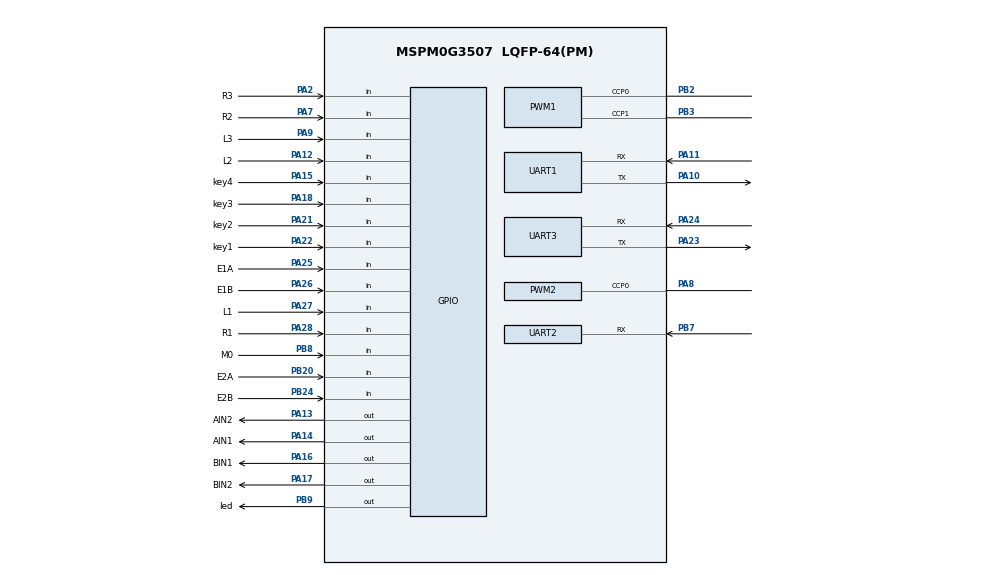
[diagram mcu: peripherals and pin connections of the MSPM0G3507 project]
/**
 * These arguments were used when this file was generated. They will be automatically applied on subsequent loads
 * via the GUI or CLI. Run CLI with '--help' for additional information on how to override these arguments.
 * @cliArgs --device "MSPM0G350X" --part "Default" --package "LQFP-64(PM)" --product "mspm0_sdk@2.05.01.00"
 * @v2CliArgs --device "MSPM0G3507" --package "LQFP-64(PM)" --product "mspm0_sdk@2.05.01.00"
 * @versions {"tool":"1.24.2+4234"}
 */

/**
 * Import the modules used in this configuration.
 */
const GPIO    = scripting.addModule("/ti/driverlib/GPIO", {}, false);
const GPIO1   = GPIO.addInstance();
const GPIO2   = GPIO.addInstance();
const GPIO3   = GPIO.addInstance();
const GPIO4   = GPIO.addInstance();
const GPIO5   = GPIO.addInstance();
const GPIO6   = GPIO.addInstance();
const GPIO7   = GPIO.addInstance();
const I2C     = scripting.addModule("/ti/driverlib/I2C", {}, false);
const I2C1    = I2C.addInstance();
const PWM     = scripting.addModule("/ti/driverlib/PWM", {}, false);
const PWM1    = PWM.addInstance();
const PWM2    = PWM.addInstance();
const SYSCTL  = scripting.addModule("/ti/driverlib/SYSCTL");
const SYSTICK = scripting.addModule("/ti/driverlib/SYSTICK");
const TIMER   = scripting.addModule("/ti/driverlib/TIMER", {}, false);
const TIMER1  = TIMER.addInstance();
const TIMER2  = TIMER.addInstance();
const UART    = scripting.addModule("/ti/driverlib/UART", {}, false);
const UART1   = UART.addInstance();
const UART2   = UART.addInstance();
const UART3   = UART.addInstance();

/**
 * Write custom configuration values to the imported modules.
 */
const divider7       = system.clockTree["PLL_PDIV"];
divider7.divideValue = 2;

const divider9       = system.clockTree["UDIV"];
divider9.divideValue = 2;

const gate7  = system.clockTree["MFCLKGATE"];
gate7.enable = true;

const multiplier2         = system.clockTree["PLL_QDIV"];
multiplier2.multiplyValue = 5;

const mux8       = system.clockTree["HSCLKMUX"];
mux8.inputSelect = "HSCLKMUX_SYSPLL2X";

GPIO1.$name                         = "KEY";
GPIO1.associatedPins.create(4);
GPIO1.associatedPins[0].direction   = "INPUT";
GPIO1.associatedPins[0].$name       = "key1";
GPIO1.associatedPins[0].pin.$assign = "PA22";
GPIO1.associatedPins[1].$name       = "key2";
GPIO1.associatedPins[1].direction   = "INPUT";
GPIO1.associatedPins[1].pin.$assign = "PA21";
GPIO1.associatedPins[2].$name       = "key3";
GPIO1.associatedPins[2].direction   = "INPUT";
GPIO1.associatedPins[2].pin.$assign = "PA18";
GPIO1.associatedPins[3].$name       = "key4";
GPIO1.associatedPins[3].direction   = "INPUT";
GPIO1.associatedPins[3].pin.$assign = "PA15";

const Board = scripting.addModule("/ti/driverlib/Board", {}, false);

GPIO2.$name                         = "LED";
GPIO2.associatedPins[0].$name       = "led";
GPIO2.associatedPins[0].pin.$assign = "PB9";

GPIO3.port                          = "PORTA";
GPIO3.$name                         = "BIN";
GPIO3.associatedPins.create(2);
GPIO3.associatedPins[0].$name       = "BIN1";
GPIO3.associatedPins[0].pin.$assign = "PA16";
GPIO3.associatedPins[1].$name       = "BIN2";
GPIO3.associatedPins[1].pin.$assign = "PA17";

GPIO4.port                          = "PORTA";
GPIO4.$name                         = "AIN";
GPIO4.associatedPins.create(2);
GPIO4.associatedPins[0].$name       = "AIN1";
GPIO4.associatedPins[0].pin.$assign = "PA14";
GPIO4.associatedPins[1].$name       = "AIN2";
GPIO4.associatedPins[1].pin.$assign = "PA13";

GPIO5.$name                               = "ENCODERA";
GPIO5.associatedPins.create(2);
GPIO5.associatedPins[0].$name             = "E1A";
GPIO5.associatedPins[0].direction         = "INPUT";
GPIO5.associatedPins[0].interruptEn       = true;
GPIO5.associatedPins[0].internalResistor  = "PULL_UP";
GPIO5.associatedPins[0].interruptPriority = "0";
GPIO5.associatedPins[0].polarity          = "RISE_FALL";
GPIO5.associatedPins[0].pin.$assign       = "PA25";
GPIO5.associatedPins[1].$name             = "E1B";
GPIO5.associatedPins[1].direction         = "INPUT";
GPIO5.associatedPins[1].interruptEn       = true;
GPIO5.associatedPins[1].internalResistor  = "PULL_UP";
GPIO5.associatedPins[1].interruptPriority = "0";
GPIO5.associatedPins[1].polarity          = "RISE_FALL";
GPIO5.associatedPins[1].pin.$assign       = "PA26";

GPIO6.$name                               = "ENCODERB";
GPIO6.associatedPins.create(2);
GPIO6.associatedPins[0].$name             = "E2A";
GPIO6.associatedPins[0].direction         = "INPUT";
GPIO6.associatedPins[0].interruptEn       = true;
GPIO6.associatedPins[0].internalResistor  = "PULL_DOWN";
GPIO6.associatedPins[0].interruptPriority = "0";
GPIO6.associatedPins[0].polarity          = "RISE_FALL";
GPIO6.associatedPins[0].pin.$assign       = "PB20";
GPIO6.associatedPins[1].$name             = "E2B";
GPIO6.associatedPins[1].direction         = "INPUT";
GPIO6.associatedPins[1].interruptEn       = true;
GPIO6.associatedPins[1].internalResistor  = "PULL_DOWN";
GPIO6.associatedPins[1].interruptPriority = "0";
GPIO6.associatedPins[1].polarity          = "RISE_FALL";
GPIO6.associatedPins[1].pin.$assign       = "PB24";

GPIO7.$name                              = "HX_X17";
GPIO7.associatedPins.create(7);
GPIO7.associatedPins[0].$name            = "L3";
GPIO7.associatedPins[0].direction        = "INPUT";
GPIO7.associatedPins[0].internalResistor = "PULL_UP";
GPIO7.associatedPins[0].pin.$assign      = "PA9";
GPIO7.associatedPins[1].$name            = "L2";
GPIO7.associatedPins[1].direction        = "INPUT";
GPIO7.associatedPins[1].internalResistor = "PULL_UP";
GPIO7.associatedPins[1].pin.$assign      = "PA12";
GPIO7.associatedPins[2].$name            = "L1";
GPIO7.associatedPins[2].direction        = "INPUT";
GPIO7.associatedPins[2].internalResistor = "PULL_UP";
GPIO7.associatedPins[2].pin.$assign      = "PA27";
GPIO7.associatedPins[3].$name            = "M0";
GPIO7.associatedPins[3].direction        = "INPUT";
GPIO7.associatedPins[3].internalResistor = "PULL_UP";
GPIO7.associatedPins[3].pin.$assign      = "PB8";
GPIO7.associatedPins[4].$name            = "R1";
GPIO7.associatedPins[4].direction        = "INPUT";
GPIO7.associatedPins[4].internalResistor = "PULL_UP";
GPIO7.associatedPins[4].pin.$assign      = "PA28";
GPIO7.associatedPins[5].$name            = "R2";
GPIO7.associatedPins[5].direction        = "INPUT";
GPIO7.associatedPins[5].internalResistor = "PULL_UP";
GPIO7.associatedPins[5].pin.$assign      = "PA7";
GPIO7.associatedPins[6].$name            = "R3";
GPIO7.associatedPins[6].direction        = "INPUT";
GPIO7.associatedPins[6].internalResistor = "PULL_UP";
GPIO7.associatedPins[6].pin.$assign      = "PA2";

I2C1.$name                             = "OLED";
I2C1.basicEnableController             = true;
I2C1.basicControllerStandardBusSpeed   = "Fast";
I2C1.sdaPinConfig.hideOutputInversion  = scripting.forceWrite(false);
I2C1.sdaPinConfig.onlyInternalResistor = scripting.forceWrite(false);
I2C1.sdaPinConfig.passedPeripheralType = scripting.forceWrite("Digital");
I2C1.sdaPinConfig.$name                = "ti_driverlib_gpio_GPIOPinGeneric8";
I2C1.sclPinConfig.hideOutputInversion  = scripting.forceWrite(false);
I2C1.sclPinConfig.onlyInternalResistor = scripting.forceWrite(false);
I2C1.sclPinConfig.passedPeripheralType = scripting.forceWrite("Digital");
I2C1.sclPinConfig.$name                = "ti_driverlib_gpio_GPIOPinGeneric9";

PWM1.$name                      = "PWM_0";
PWM1.timerStartTimer            = true;
PWM1.pwmMode                    = "EDGE_ALIGN_UP";
PWM1.timerCount                 = 8000;
PWM1.peripheral.$assign         = "TIMA1";
PWM1.peripheral.ccp0Pin.$assign = "PB2";
PWM1.peripheral.ccp1Pin.$assign = "PB3";
PWM1.PWM_CHANNEL_0.$name        = "ti_driverlib_pwm_PWMTimerCC0";
PWM1.PWM_CHANNEL_1.$name        = "ti_driverlib_pwm_PWMTimerCC1";
PWM1.ccp0PinConfig.$name        = "ti_driverlib_gpio_GPIOPinGeneric4";
PWM1.ccp1PinConfig.$name        = "ti_driverlib_gpio_GPIOPinGeneric5";

PWM2.$name                      = "PWM_1";
PWM2.ccIndex                    = [0];
PWM2.PWM_CHANNEL_0.$name        = "ti_driverlib_pwm_PWMTimerCC2";
PWM2.ccp0PinConfig.$name        = "ti_driverlib_gpio_GPIOPinGeneric0";
PWM2.peripheral.ccp0Pin.$assign = "PA8";

SYSCTL.forceDefaultClkConfig = true;
SYSCTL.clockTreeEn           = true;
scripting.suppress("For best practices when the CPUCLK is running at 32MHz and above, clear the flash status bit using DL_FlashCTL_executeClearStatus\\(\\) before executing any flash operation\\. Otherwise there may be false positives\\.", SYSCTL);

SYSTICK.periodEnable  = true;
SYSTICK.systickEnable = true;
SYSTICK.period        = 16777216;

TIMER1.$name              = "TIMER_0";
TIMER1.timerClkPrescale   = 32;
TIMER1.timerMode          = "PERIODIC";
TIMER1.timerStartTimer    = true;
TIMER1.interrupts         = ["ZERO"];
TIMER1.timerPeriod        = "10 ms";
TIMER1.interruptPriority  = "0";
TIMER1.peripheral.$assign = "TIMG0";

TIMER2.$name              = "TIMER_1";
TIMER2.timerMode          = "PERIODIC";
TIMER2.timerPeriod        = "100 ms";
TIMER2.interrupts         = ["ZERO"];
TIMER2.timerClkPrescale   = 64;
TIMER2.timerStartTimer    = true;
TIMER2.interruptPriority  = "1";
TIMER2.peripheral.$assign = "TIMG8";

UART1.$name                    = "UART_0";
UART1.profile                  = "CONFIG_PROFILE_1";
UART1.peripheral.rxPin.$assign = "PA11";
UART1.peripheral.txPin.$assign = "PA10";
UART1.txPinConfig.$name        = "ti_driverlib_gpio_GPIOPinGeneric2";
UART1.rxPinConfig.$name        = "ti_driverlib_gpio_GPIOPinGeneric3";

UART2.$name                            = "UART_JY61P";
UART2.direction                        = "RX";
UART2.enableFIFO                       = true;
UART2.rxTimeoutValue                   = 1;
UART2.enabledInterrupts                = ["RX_TIMEOUT_ERROR"];
UART2.enabledDMARXTriggers             = "DL_UART_DMA_INTERRUPT_RX";
UART2.targetBaudRate                   = 115200;
UART2.rxPinConfig.hideOutputInversion  = scripting.forceWrite(false);
UART2.rxPinConfig.onlyInternalResistor = scripting.forceWrite(false);
UART2.rxPinConfig.passedPeripheralType = scripting.forceWrite("Digital");
UART2.rxPinConfig.$name                = "ti_driverlib_gpio_GPIOPinGeneric1";
UART2.peripheral.rxPin.$assign         = "PB7";
UART2.DMA_CHANNEL_RX.$name             = "DMA_WIT";
UART2.DMA_CHANNEL_RX.addressMode       = "f2b";
UART2.DMA_CHANNEL_RX.srcLength         = "BYTE";
UART2.DMA_CHANNEL_RX.dstLength         = "BYTE";

UART3.$name                            = "UART_BT";
UART3.enabledDMARXTriggers             = "DL_UART_DMA_INTERRUPT_RX";
UART3.peripheral.rxPin.$assign         = "PA24";
UART3.peripheral.txPin.$assign         = "PA23";
UART3.txPinConfig.direction            = scripting.forceWrite("OUTPUT");
UART3.txPinConfig.hideOutputInversion  = scripting.forceWrite(false);
UART3.txPinConfig.onlyInternalResistor = scripting.forceWrite(false);
UART3.txPinConfig.passedPeripheralType = scripting.forceWrite("Digital");
UART3.txPinConfig.$name                = "ti_driverlib_gpio_GPIOPinGeneric6";
UART3.rxPinConfig.hideOutputInversion  = scripting.forceWrite(false);
UART3.rxPinConfig.onlyInternalResistor = scripting.forceWrite(false);
UART3.rxPinConfig.passedPeripheralType = scripting.forceWrite("Digital");
UART3.rxPinConfig.$name                = "ti_driverlib_gpio_GPIOPinGeneric7";
UART3.DMA_CHANNEL_RX.$name             = "DMA_CH0";
UART3.DMA_CHANNEL_RX.addressMode       = "f2b";
UART3.DMA_CHANNEL_RX.srcLength         = "BYTE";
UART3.DMA_CHANNEL_RX.dstLength         = "BYTE";

/**
 * Pinmux solution for unlocked pins/peripherals. This ensures that minor changes to the automatic solver in a future
 * version of the tool will not impact the pinmux you originally saw.  These lines can be completely deleted in order to
 * re-solve from scratch.
 */
Board.peripheral.$suggestSolution                = "DEBUGSS";
Board.peripheral.swclkPin.$suggestSolution       = "PA20";
Board.peripheral.swdioPin.$suggestSolution       = "PA19";
I2C1.peripheral.$suggestSolution                 = "I2C0";
I2C1.peripheral.sdaPin.$suggestSolution          = "PA0";
I2C1.peripheral.sclPin.$suggestSolution          = "PA1";
PWM2.peripheral.$suggestSolution                 = "TIMA0";
UART1.peripheral.$suggestSolution                = "UART0";
UART2.peripheral.$suggestSolution                = "UART1";
UART2.DMA_CHANNEL_RX.peripheral.$suggestSolution = "DMA_CH1";
UART3.peripheral.$suggestSolution                = "UART2";
UART3.DMA_CHANNEL_RX.peripheral.$suggestSolution = "DMA_CH0";
